# AT32UC3B0256 device description
Architecture: AVR32_UC3; Family: AVR UC3
Registers are 32-bit, read-write, reset 0x0 unless marked. A register's access mark holds for its fields unless they carry their own. Offsets are from the block's base; [hi:lo] are bit positions; lines under a group give offsets from that group; {n}, {i} and the like mark numbered series; 'fields as' and 'values as' point back to an identical list.

## HMATRIX — HSB Matrix
Instances: HMATRIX 0xfffe1000
{0x0+4i} mcfg[{i}] (i=0..15) access not given reset not defined
  [2:0] ULBT — Undefined Length Burst Type
    0=INFINITE; 1=SINGLE; 2=FOUR_BEAT; 3=EIGHT_BEAT; 4=SIXTEEN_BEAT
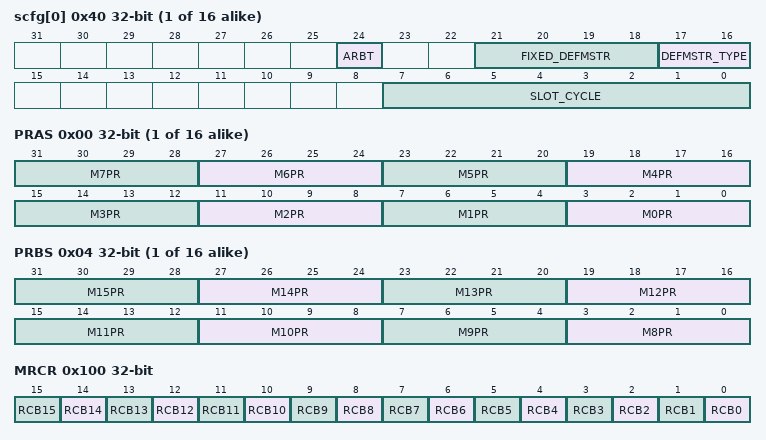
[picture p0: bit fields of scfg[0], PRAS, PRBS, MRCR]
{0x40+4i} scfg[{i}] (i=0..15) access not given reset not defined
  [24] ARBT — Arbitration Type
    0=ROUND_ROBIN; 1=FIXED_PRIORITY
  [21:18] FIXED_DEFMSTR — Fixed Index of Default Master
  [17:16] DEFMSTR_TYPE — Default Master Type
    0=NO_DEFAULT; 1=LAST_DEFAULT; 2=FIXED_DEFAULT
  [7:0] SLOT_CYCLE — Maximum Number of Allowed Cycles for a Burst
{0x80+8i} prs[{i}] (i=0..15) group
  0x00 PRAS — Priority Register A for Slave 0
    [4n+3:4n] M{n}PR (n=0..7) — Master {n} Priority
  0x04 PRBS — Priority Register B for Slave 0
    [4n-29:4n-32] M{n}PR (n=8..15) — Master {n} Priority
0x100 MRCR — Master Remap Control Register
  [n] RCB{n} (n=0..15) — Remap Command bit for Master {n}
{0x110+4i} sfr[{i}] (i=0..15) access not given
  [31:0] SFR — Special Function Register

## PDCA — Peripheral DMA Controller
Instances: PDCA 0xffff0000
{0x0+0x40*i} channel[{i}] (i=0..31) group
  0x00 MAR — Memory Address Register
    [31:0] MADDR — Memory Address
  0x04 PSR — Peripheral Select Register
    [7:0] PID — Peripheral Identifier
  0x08 TCR — Transfer Counter Register
    [15:0] TCV — Transfer Counter Value
  0x0C MARR — Memory Address Reload Register
    [31:0] MARV — Memory Address Reload Value
  0x10 TCRR — Transfer Counter Reload Register
    [15:0] TCRV — Transfer Counter Reload Value
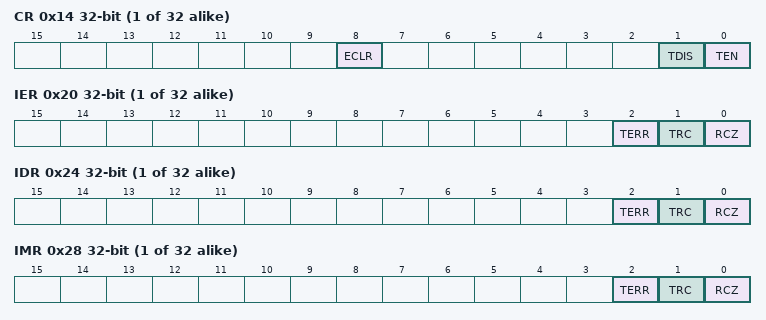
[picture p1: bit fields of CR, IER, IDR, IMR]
  0x14 CR wo — Control Register
    [8] ECLR — Error Clear
    [1] TDIS — Transfer Disable
    [0] TEN — Transfer Enable
  0x18 MR — Mode Register
    [1:0] SIZE — Transfer size
      0=Byte; 1=Half_Word; 2=Word
  0x1C SR ro — Status Register
    [0] TEN — Transfer Enabled
  0x20 IER wo — Interrupt Enable Register
    [2] TERR — Transfer Error
    [1] TRC — Transfer Complete
    [0] RCZ — Reload Counter Zero
  0x24 IDR wo — Interrupt Disable Register
    fields as channel[0].IER
  0x28 IMR ro — Interrupt Mask Register
    fields as channel[0].IER
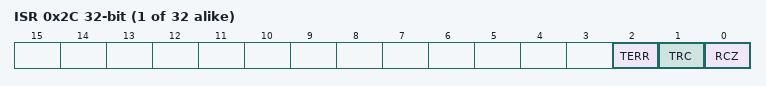
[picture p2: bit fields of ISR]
  0x2C ISR ro — Interrupt Status Register
    fields as channel[0].IER

## PWM — Pulse Width Modulation Controller
Instances: PWM 0xffff3000
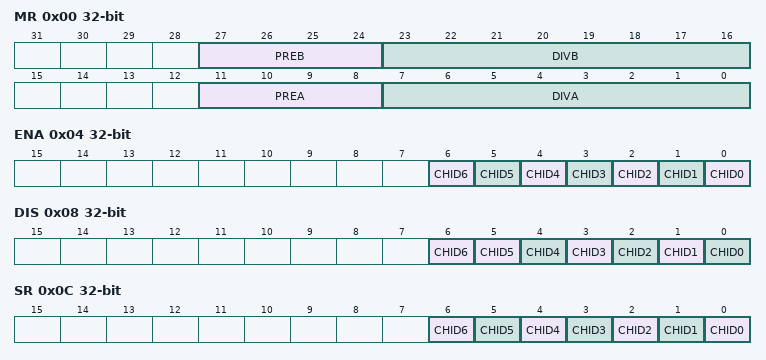
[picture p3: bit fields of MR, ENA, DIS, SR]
0x00 MR — PWM Mode Register
  [27:24] PREB
    0=MCK; 1=MCK_DIV_2; 2=MCK_DIV_4; 3=MCK_DIV_8; 4=MCK_DIV_16; 5=MCK_DIV_32; 6=MCK_DIV_64; 7=MCK_DIV_128; 8=MCK_DIV_256; 9=MCK_DIV_512; 10=MCK_DIV_1024
  [23:16] DIVB — CLKB divide factor
    0=CLK_OFF; 1=CLK_SEL_PREAB
  [11:8] PREA
    values as PREB
  [7:0] DIVA — CLKA divide factor
    0=CLK_OFF; 1=CLK_SEL_PREAB
0x04 ENA wo reset not defined — PWM Enable Register
  [n] CHID{n} (n=0..6) — Channel ID {n}
0x08 DIS wo reset not defined — PWM Disable Register
  [6] CHID6 — Channel ID 3
  [n] CHID{n} (n=0..5) — Channel ID {n}
0x0C SR ro — PWM Status Register
  [n] CHID{n} (n=0..6) — Channel ID {n}
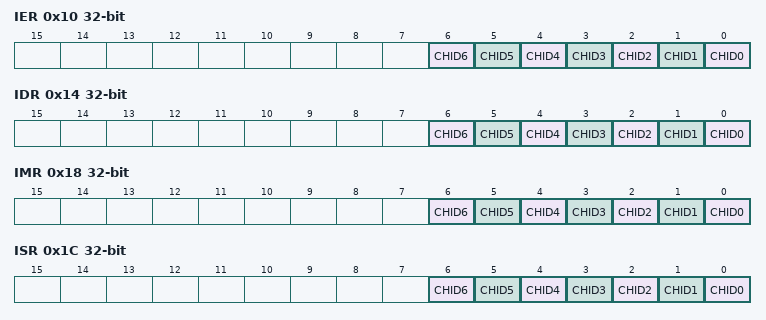
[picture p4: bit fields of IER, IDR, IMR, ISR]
0x10 IER wo reset not defined — PWM Interrupt Enable Register
  [n] CHID{n} (n=0..6) — Channel ID {n}
0x14 IDR wo reset not defined — PWM Interrupt Disable Register
  [n] CHID{n} (n=0..6) — Channel ID {n}
0x18 IMR ro — PWM Interrupt Mask Register
  [n] CHID{n} (n=0..6) — Channel ID {n}
0x1C ISR ro — PWM Interrupt Status Register
  [n] CHID{n} (n=0..6) — Channel ID {n}
{0x200+0x20*i} channel[{i}] (i=0..31) group
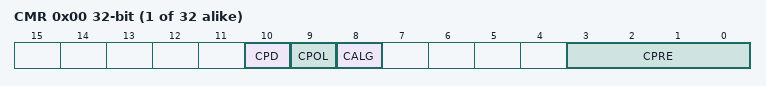
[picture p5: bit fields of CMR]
  0x00 CMR — PWM Channel Mode Register 0
    [10] CPD — Channel Update Period
    [9] CPOL — Channel Polarity
    [8] CALG — Channel Alignment
    [3:0] CPRE — Channel pre-scaler
      0=MCK; 1=MCK_DIV_2; 2=MCK_DIV_4; 3=MCK_DIV_8; 4=MCK_DIV_16; 5=MCK_DIV_32; 6=MCK_DIV_64; 7=MCK_DIV_128; 8=MCK_DIV_256; 9=MCK_DIV_512; 10=MCK_DIV_1024; 11=CLKA; 12=CLKB
  0x04 CDTY — PWM Channel Duty Cycle Register 0
    [31:0] CDTY — Channel Duty Cycle
  0x08 CPRD — PWM Channel Period Register 0
    [31:0] CPRD — Channel Period
  0x0C CCNT ro — PWM Channel Counter Register 0
    [31:0] CNT — Channel Counter Register
  0x10 CUPD wo reset not defined — PWM Channel Update Register 0
